VERSION ""

NS_ :

BS_:

BU_: ADAS Body TBOX PC HU GW

BO_ 258 APC_2: 8 ADAS
 SG_ Acceleration : 8|8@1- (0.5,-64) [-64|63.5] "m/s"  GW
 SG_ AEBLvl : 0|2@1+ (1,0) [0|3] ""  HU,GW

BO_ 257 APC_1: 8 GW
 SG_ AEBCmd : 0|1@1+ (1,0) [0|1] ""  GW,ADAS

BO_ 210 EPS_3: 8 Vector__XXX
 SG_ SteeringWheelAngle : 8|12@1- (0.5,-1024) [-1024|1023.5] "°"  GW,PC

BO_ 225 EMS_2: 8 GW
 SG_ ThrottlePedalPosition : 8|8@1+ (0.5,0) [0|127.5] "°"  PC,GW
 SG_ BrakePedalPosition : 0|8@1+ (0.5,0) [0|127.5] "°"  PC,GW

BO_ 209 EPS_2: 8 GW
 SG_ SteeringForceFeedback : 0|8@1- (1,-128) [-128|127] ""  GW

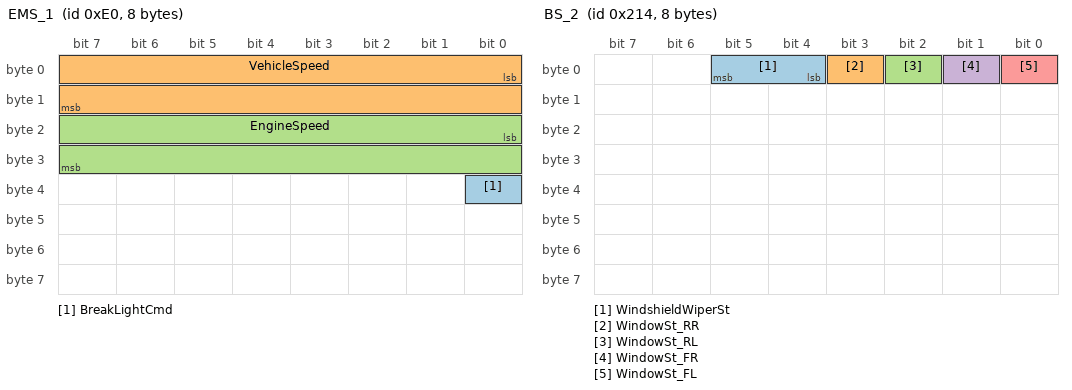
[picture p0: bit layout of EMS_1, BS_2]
BO_ 224 EMS_1: 8 GW
 SG_ BreakLightCmd : 32|1@1+ (1,0) [0|0] ""  GW,Body
 SG_ VehicleSpeed : 0|16@1- (1,-128) [-128|240] "km/h"  GW,ADAS,HU
 SG_ EngineSpeed : 16|16@1+ (1,0) [0|10000] "rpm"  HU,GW

BO_ 208 EPS_1: 8 GW
 SG_ SteeringAngle : 0|8@1- (0.5,-64) [-64|63.5] "°"  GW

BO_ 532 BS_2: 8 GW
 SG_ WindshieldWiperSt : 4|2@1+ (1,0) [0|3] ""  HU,GW
 SG_ WindowSt_RR : 3|1@1+ (1,0) [0|1] ""  GW
 SG_ WindowSt_RL : 2|1@1+ (1,0) [0|1] ""  GW
 SG_ WindowSt_FR : 1|1@1+ (1,0) [0|1] ""  GW
 SG_ WindowSt_FL : 0|1@1+ (1,0) [0|1] ""  GW

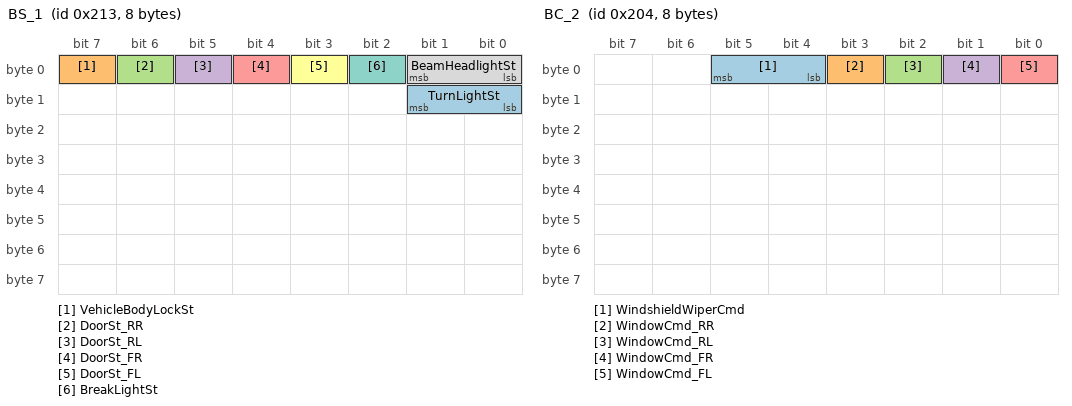
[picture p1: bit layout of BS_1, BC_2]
BO_ 531 BS_1: 8 GW
 SG_ TurnLightSt : 8|2@1+ (1,0) [0|2] ""  HU,GW
 SG_ VehicleBodyLockSt : 7|1@1+ (1,0) [0|1] ""  TBOX,HU,GW
 SG_ DoorSt_RR : 6|1@1+ (1,0) [0|1] ""  GW
 SG_ DoorSt_RL : 5|1@1+ (1,0) [0|1] ""  GW
 SG_ DoorSt_FR : 4|1@1+ (1,0) [0|1] ""  GW
 SG_ DoorSt_FL : 3|1@1+ (1,0) [0|1] ""  GW
 SG_ BreakLightSt : 2|1@1+ (1,0) [0|0] ""  GW
 SG_ BeamHeadlightSt : 0|2@1+ (1,0) [0|3] ""  HU,GW

BO_ 516 BC_2: 8 GW
 SG_ WindshieldWiperCmd : 4|2@1+ (1,0) [0|3] ""  Body,GW
 SG_ WindowCmd_RR : 3|1@1+ (1,0) [0|1] ""  Body,GW
 SG_ WindowCmd_RL : 2|1@1+ (1,0) [0|1] ""  Body,GW
 SG_ WindowCmd_FR : 1|1@1+ (1,0) [0|1] ""  Body,GW
 SG_ WindowCmd_FL : 0|1@1+ (1,0) [0|1] ""  Body,GW

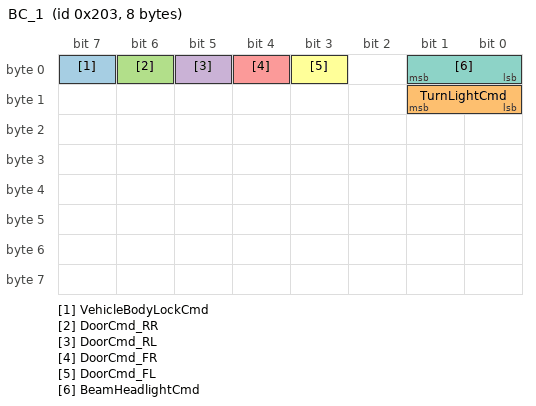
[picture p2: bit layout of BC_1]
BO_ 515 BC_1: 8 GW
 SG_ VehicleBodyLockCmd : 7|1@1+ (1,0) [0|1] ""  Body,GW
 SG_ TurnLightCmd : 8|2@1+ (1,0) [0|2] ""  Body,GW
 SG_ DoorCmd_RR : 6|1@1+ (1,0) [0|1] ""  Body,GW
 SG_ DoorCmd_RL : 5|1@1+ (1,0) [0|1] ""  Body,GW
 SG_ DoorCmd_FR : 4|1@1+ (1,0) [0|1] ""  Body,GW
 SG_ DoorCmd_FL : 3|1@1+ (1,0) [0|1] ""  Body,GW
 SG_ BeamHeadlightCmd : 0|2@1+ (1,0) [0|3] ""  Body,GW

BO_ 240 TCU_1: 8 GW
 SG_ Gear : 0|4@1- (1,-1) [-1|7] ""  HU,PC,GW

BO_TX_BU_ 258 : PC,GW,ADAS;
BO_TX_BU_ 209 : PC,GW;
BO_TX_BU_ 224 : PC,GW;
BO_TX_BU_ 208 : PC,GW;
BO_TX_BU_ 532 : Body,GW;
BO_TX_BU_ 531 : Body,GW;
BO_TX_BU_ 515 : TBOX,GW;
BO_TX_BU_ 240 : PC,GW;

CM_ BU_ Body "This node is to conctrl windows";
CM_ SG_ 258 Acceleration "Minus indicates deceleration, plus indicates acceleration.";
CM_ SG_ 258 AEBLvl "0:NA,1:low,2:mid,3:higth";
CM_ SG_ 257 AEBCmd "0:off,1:on";
CM_ SG_ 210 SteeringWheelAngle "Minus indicates turning left, plus indicates turning right.";
CM_ SG_ 225 ThrottlePedalPosition "0 indicates that the throttle is not applied";
CM_ SG_ 225 BrakePedalPosition "0 indicates that the brake is not applied";
CM_ SG_ 209 SteeringForceFeedback "todo:details";
CM_ SG_ 224 BreakLightCmd "0:off,1:on";
CM_ SG_ 224 VehicleSpeed "Minus indicates reverse, plus indicates forward.";
CM_ SG_ 208 SteeringAngle "Minus indicates turning left, plus indicates turning right.";
CM_ SG_ 532 WindowSt_RR "0:off,1:on";
CM_ SG_ 532 WindowSt_RL "0:off,1:on";
CM_ SG_ 532 WindowSt_FR "0:off,1:on";
CM_ SG_ 532 WindowSt_FL "0:off,1:on";
CM_ SG_ 531 TurnLightSt "0:off,1:left,2:right";
CM_ SG_ 531 VehicleBodyLockSt "0:off,1:on";
CM_ SG_ 531 DoorSt_RR "0:off,1:on";
CM_ SG_ 531 DoorSt_RL "0:off,1:on";
CM_ SG_ 531 DoorSt_FR "0:off,1:on";
CM_ SG_ 531 DoorSt_FL "0:off,1:on";
CM_ SG_ 531 BreakLightSt "0:off,1:on";
CM_ SG_ 531 BeamHeadlightSt "0:off,1:low,2:high";
CM_ BO_ 516 "This message is to conctrl windows and Wiper.";
CM_ SG_ 516 WindshieldWiperCmd "0:off,1:slow,2:mid,3:fast";
CM_ SG_ 516 WindowCmd_RR "0:off,1:on";
CM_ SG_ 516 WindowCmd_RL "0:off,1:on";
CM_ SG_ 516 WindowCmd_FR "0:off,1:on";
CM_ SG_ 516 WindowCmd_FL "0:off,1:on";
CM_ BO_ 515 "This message is to conctrl doors and lights.";
CM_ SG_ 515 VehicleBodyLockCmd "0:off,1:on";
CM_ SG_ 515 TurnLightCmd "0:off,1:left,2:right";
CM_ SG_ 515 DoorCmd_RR "0:off,1:on";
CM_ SG_ 515 DoorCmd_RL "0:off,1:on";
CM_ SG_ 515 DoorCmd_FR "0:off,1:on";
CM_ SG_ 515 DoorCmd_FL "0:off,1:on";
CM_ SG_ 515 BeamHeadlightCmd "0:off,1:low,2:high";
CM_ SG_ 240 Gear "-1 indicates reverse gear";
BA_DEF_ BO_  "GenMsgCycleTime" INT 0 0;
BA_DEF_ BO_  "CANFD_BRS" ENUM  "0","1";
BA_DEF_  "DBName" STRING ;
BA_DEF_  "BusType" STRING ;
BA_DEF_ BO_  "VFrameFormat" ENUM  "StandardCAN","ExtendedCAN","reserved","reserved","reserved","reserved","reserved","reserved","reserved","reserved","reserved","reserved","reserved","reserved","StandardCAN_FD","ExtendedCAN_FD";
BA_DEF_DEF_  "GenMsgCycleTime" 20;
BA_DEF_DEF_  "CANFD_BRS" "1";
BA_DEF_DEF_  "DBName" "";
BA_DEF_DEF_  "BusType" "";
BA_DEF_DEF_  "VFrameFormat" "StandardCAN";
BA_ "BusType" "CAN FD";
BA_ "DBName" "zhongshan";
BA_ "GenMsgCycleTime" BO_ 258 50;
BA_ "GenMsgCycleTime" BO_ 257 50;
BA_ "GenMsgCycleTime" BO_ 210 50;
BA_ "GenMsgCycleTime" BO_ 225 50;
BA_ "GenMsgCycleTime" BO_ 209 50;
BA_ "GenMsgCycleTime" BO_ 224 50;
BA_ "GenMsgCycleTime" BO_ 208 50;
BA_ "GenMsgCycleTime" BO_ 532 100;
BA_ "GenMsgCycleTime" BO_ 531 100;
BA_ "GenMsgCycleTime" BO_ 516 100;
BA_ "GenMsgCycleTime" BO_ 515 100;
BA_ "GenMsgCycleTime" BO_ 240 50;

BO_ 384 VEH_WARN_ABS: 8 GW
 SG_ ABSWarn : 0|1@1+ (1,0) [0|1] ""  HU

BO_ 385 VEH_ERR_BRAKE: 8 GW
 SG_ BrakingSysErr : 0|1@1+ (1,0) [0|1] ""  HU

BO_ 386 VEH_ERR_CHARGING: 8 GW
 SG_ ChargingSysErr : 0|1@1+ (1,0) [0|1] ""  HU

BO_ 387 VEH_ERR_ENGINE: 8 GW
 SG_ EngineErr : 0|1@1+ (1,0) [0|1] ""  HU

BO_ 388 VEH_WARN_ESP: 8 GW
 SG_ ESPWarn : 0|1@1+ (1,0) [0|1] ""  HU

BO_ 389 VEH_WARN_OVERHEAT: 8 GW
 SG_ EngineOverheat : 0|1@1+ (1,0) [0|1] ""  HU

BO_ 390 VEH_WARN_LOW_OIL: 8 GW
 SG_ LowEngineOil : 0|1@1+ (1,0) [0|1] ""  HU

BO_ 391 VEH_WARN_TPMS: 8 GW
 SG_ TirePressure : 0|1@1+ (1,0) [0|1] ""  HU

BO_ 392 VEH_WARN_MASTER: 8 GW
 SG_ MasterWarning : 0|1@1+ (1,0) [0|1] ""  HU

BO_ 393 VEH_WARN_AIRBAG: 8 GW
 SG_ Airbag : 0|1@1+ (1,0) [0|1] ""  HU
